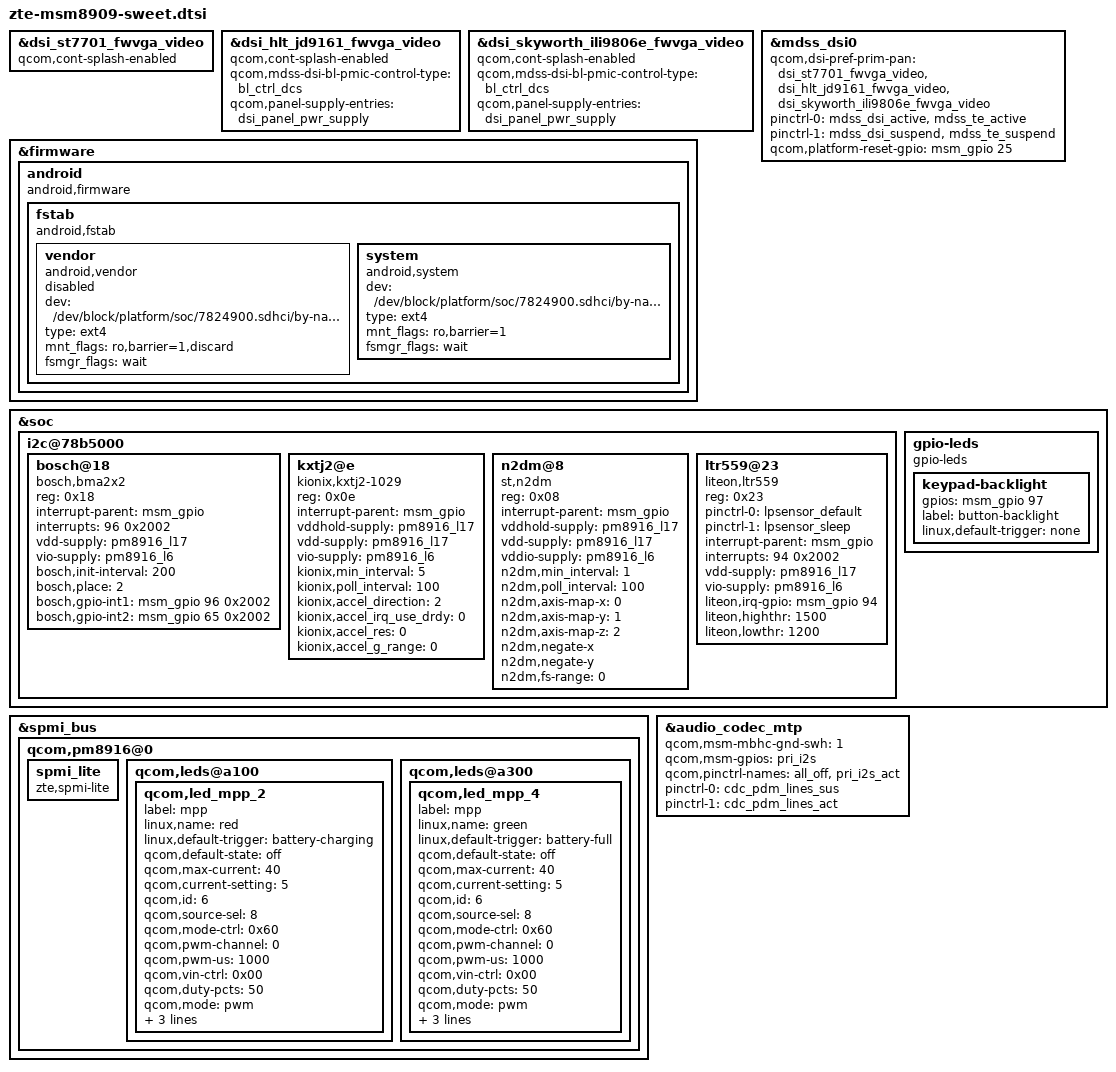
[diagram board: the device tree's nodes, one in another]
#include "dsi-panel-zte-lead-cpt-st7701-5p0-fwvga-video.dtsi"
#include "dsi-panel-zte-helitai-hsd-jd9161-fwvga-video.dtsi"
#include "dsi_panel_zte_skyworth_ili9806e_cpt_5p0_fwvga_video.dtsi"

#include "touch-key-backlight-sweet.dtsi"


&dsi_st7701_fwvga_video {
	qcom,cont-splash-enabled;
};

&dsi_hlt_jd9161_fwvga_video {
	qcom,cont-splash-enabled;
	qcom,mdss-dsi-bl-pmic-control-type = "bl_ctrl_dcs";
	qcom,panel-supply-entries = <&dsi_panel_pwr_supply>;
};

&dsi_skyworth_ili9806e_fwvga_video {
	qcom,cont-splash-enabled;
	qcom,mdss-dsi-bl-pmic-control-type = "bl_ctrl_dcs";
	qcom,panel-supply-entries = <&dsi_panel_pwr_supply>;
};

&mdss_dsi0 {
	qcom,dsi-pref-prim-pan = <&dsi_st7701_fwvga_video &dsi_hlt_jd9161_fwvga_video
				&dsi_skyworth_ili9806e_fwvga_video>;
	pinctrl-names = "mdss_default", "mdss_sleep";
	pinctrl-0 = <&mdss_dsi_active &mdss_te_active>;
	pinctrl-1 = <&mdss_dsi_suspend &mdss_te_suspend>;

	qcom,platform-reset-gpio = <&msm_gpio 25 0>;
};

&firmware {
	android {
		compatible = "android,firmware";
		fstab {
			compatible = "android,fstab";
			vendor {
				compatible = "android,vendor";
				dev = "/dev/block/platform/soc/7824900.sdhci/by-name/vendor";
				type = "ext4";
				mnt_flags = "ro,barrier=1,discard";
				fsmgr_flags = "wait";
				status = "disabled";
			};
			system {
				compatible = "android,system";
				dev = "/dev/block/platform/soc/7824900.sdhci/by-name/system";
				type = "ext4";
				mnt_flags = "ro,barrier=1";
				fsmgr_flags = "wait";
				status = "ok";
			};
		};
	};
};

&soc {
	i2c@78b5000 { /* BLSP1 QUP1 */
		bosch@18 { /* Accelerometer sensor */
			compatible = "bosch,bma2x2";
			reg = <0x18>;
			interrupt-parent = <&msm_gpio>;
			interrupts = <96 0x2002>;
			vdd-supply = <&pm8916_l17>;
			vio-supply = <&pm8916_l6>;
			bosch,init-interval = <200>;
			bosch,place = <2>;
			bosch,gpio-int1 = <&msm_gpio 96 0x2002>;
			bosch,gpio-int2 = <&msm_gpio 65 0x2002>;
		};

		kxtj2@e {
			compatible = "kionix,kxtj2-1029";
			reg = <0x0e>;
			interrupt-parent = <&msm_gpio>;
			/*interrupts = <96 0x2>;*/
			vddhold-supply = <&pm8916_l17>;
			vdd-supply = <&pm8916_l17>;
			vio-supply = <&pm8916_l6>;
			kionix,min_interval = <5>;
			kionix,poll_interval = <100>;
			kionix,accel_direction = <2>;
			kionix,accel_irq_use_drdy = <0>;
			/*0 is 12BIT,	1 is 8BIT,	2 is 6BIT*/
			kionix,accel_res = <0>;
			/*0 is 2g,	1 is 4g,	2 is 6g,	3 is 8g*/
			kionix,accel_g_range =	<0>;
		};

		n2dm@8 {
			compatible = "st,n2dm";
			reg = <0x08>;
			interrupt-parent = <&msm_gpio>;
			/*interrupts = <96 0x2>;*/
			vddhold-supply = <&pm8916_l17>;
			vdd-supply = <&pm8916_l17>;
			vddio-supply = <&pm8916_l6>;
			n2dm,min_interval = <1>;
			n2dm,poll_interval = <100>;
			n2dm,axis-map-x = <0>;
			n2dm,axis-map-y = <1>;
			n2dm,axis-map-z = <2>;
			n2dm,negate-x;
			n2dm,negate-y;
			//n2dm,negate-z;
			/*0 is 2g,	16 is 4g,	32 is 8g,	48 is 16g*/
			n2dm,fs-range = <0>;
		};

		ltr559@23 {
			compatible = "liteon,ltr559";
			reg = <0x23>;
			pinctrl-names = "lpsensor_default", "lpsensor_sleep";
			pinctrl-0 = <&lpsensor_default>;
			pinctrl-1 = <&lpsensor_sleep>;
			interrupt-parent = <&msm_gpio>;
			interrupts = <94 0x2002>;
			vdd-supply = <&pm8916_l17>;
			vio-supply = <&pm8916_l6>;
			liteon,irq-gpio = <&msm_gpio 94 0x2002>;
			liteon,highthr = <1500>;
			liteon,lowthr = <1200>;
		};
/*
		akm@c {
			compatible = "ak,ak09911";
			reg = <0x0c>;
			vdd-supply = <&pm8916_l17>;
			vio-supply = <&pm8916_l6>;
			akm,layout = <0x2>;
			akm,auto-report;
		};
*/
	};
	/*zte_pm add for button light*/
		gpio-leds {
			compatible = "gpio-leds";
			keypad-backlight {
				gpios = <&msm_gpio 97 0>;
				label = "button-backlight";
				linux,default-trigger = "none";
			};
		};
		/*end*/
};

&spmi_bus {
	qcom,pm8916@0 {
		/*spmi_lite is for batt present detect*/
		spmi_lite {
			compatible = "zte,spmi-lite";
		};
	};
	qcom,pm8916@0 {
		qcom,leds@a100 {
			status = "okay";
			qcom,led_mpp_2 {	/* red led */
				label = "mpp";
				linux,name = "red";
				linux,default-trigger = "battery-charging";
				qcom,default-state = "off";
				qcom,max-current = <40>;
				qcom,current-setting = <5>;
				qcom,id = <6>;
				qcom,source-sel = <8>;
				qcom,mode-ctrl = <0x60>;
				qcom,pwm-channel = <0>;
				qcom,pwm-us = <1000>;
				qcom,vin-ctrl = <0x00>;
				qcom,duty-pcts = <50>;
				qcom,mode = "pwm";
				qcom,use-blink;
				pwms = <&pm8916_pwm 0 0>;
				qcom,pwm-names = "red-led";
			};
		};

		qcom,leds@a300 {
			status = "okay";
			qcom,led_mpp_4 {	/* green led */
				label = "mpp";
				linux,name = "green";		/* orgin is wled-backlight */
				linux,default-trigger = "battery-full";	/* org="bkl-trigger"; */
				qcom,default-state = "off";
				qcom,max-current = <40>;
				qcom,current-setting = <5>;	/* zte add */
				qcom,id = <6>;				/* in leds-qpnp.c enum QPNP_ID_LED_MPP(6) */
				qcom,source-sel = <8>;		/* select power source, default 1 (enabled)(org=8) */
				qcom,mode-ctrl = <0x60>;	/* operation mode, default 0x60 = Mode Sink (org=0x10)*/
				qcom,pwm-channel = <0>;
				qcom,pwm-us = <1000>;
				qcom,vin-ctrl = <0x00>;		/* select input source, 0 to 3 */
				qcom,duty-pcts = <50>;
				qcom,mode = "pwm";
				qcom,use-blink;
				pwms = <&pm8916_pwm 0 0>;
				qcom,pwm-names = "green-led";
			};
		};
	};
};
&audio_codec_mtp {
	qcom,msm-mbhc-gnd-swh = <1>;
	qcom,msm-gpios =
		"pri_i2s";
	qcom,pinctrl-names =
		"all_off",
		"pri_i2s_act";
	pinctrl-names =
		"all_off",
		"pri_i2s_act";
	pinctrl-0 = <&cdc_pdm_lines_sus>;
	pinctrl-1 = <&cdc_pdm_lines_act>;
	/delete-property/ pinctrl-2;
	/delete-property/ pinctrl-3;
	/delete-property/ qcom,cdc-us-euro-gpios;
};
